# RX64M_PORT_Pilot register map
File version: 1.0
RX64M_PORT_Pilot peripheral registers generated from iodefine.h (pilot).
Registers are 8-bit, read-write, reset 0x0 unless marked. A register's access mark holds for its fields unless they carry their own. Offsets are from the block's base; lines under a group give offsets from that group; [hi:lo] are bit positions; {n}, {i} and the like mark numbered series; 'fields as' and 'values as' point back to an identical list; <NAME> marks a mode.

## Memory map
0x0008C000 PORT0 size 0xE1
0x0008C001 PORT1 size 0xC1
0x0008C002 PORT2 size 0xE1
0x0008C003 PORT3 size 0xC1
0x0008C004 PORT4 size 0xC1
0x0008C005 PORT5 size 0xE1
0x0008C006 PORT6 size 0xC1
0x0008C007 PORT7 size 0xC1
0x0008C008 PORT8 size 0xC1
0x0008C009 PORT9 size 0xE1
0x0008C00A PORTA size 0xE1
0x0008C00B PORTB size 0xE1
0x0008C00C PORTC size 0xE1
0x0008C00D PORTD size 0xE1
0x0008C00E PORTE size 0xE1
0x0008C00F PORTF size 0xC1
0x0008C010 PORTG size 0xE1
0x0008C012 PORTJ size 0xC1

## PORT0
Base 0x0008C000
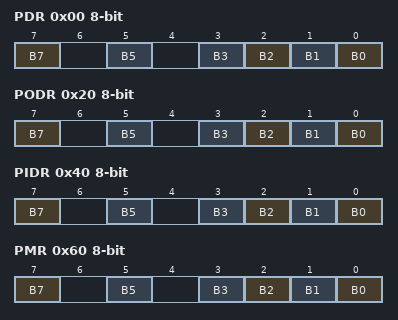
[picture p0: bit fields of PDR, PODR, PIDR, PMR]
0x00 PDR
  [7] B7, [5] B5, [n] B{n} (n=0..3)
0x20 PODR
  [7] B7, [5] B5, [n] B{n} (n=0..3)
0x40 PIDR ro reset not defined
  [7] B7, [5] B5, [n] B{n} (n=0..3)
0x60 PMR
  [7] B7, [5] B5, [n] B{n} (n=0..3)
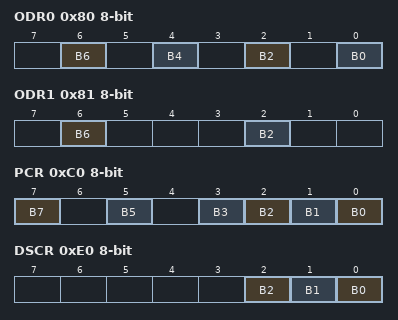
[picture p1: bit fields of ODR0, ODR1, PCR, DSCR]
0x80 ODR0
  [6] B6, [4] B4, [2] B2, [0] B0
0x81 ODR1
  [6] B6, [2] B2
0xC0 PCR
  [7] B7, [5] B5, [n] B{n} (n=0..3)
0xE0 DSCR
  [2] B2, [1] B1, [0] B0

## PORT1
Base 0x0008C001
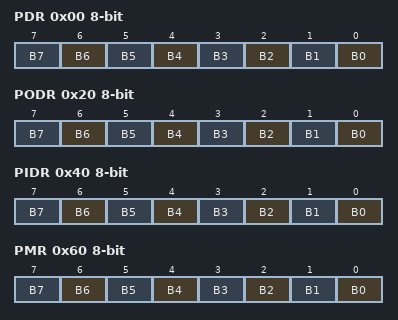
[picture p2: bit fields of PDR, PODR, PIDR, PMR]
0x00 PDR
  [n] B{n} (n=0..7)
0x20 PODR
  [n] B{n} (n=0..7)
0x40 PIDR ro reset not defined
  [n] B{n} (n=0..7)
0x60 PMR
  [n] B{n} (n=0..7)
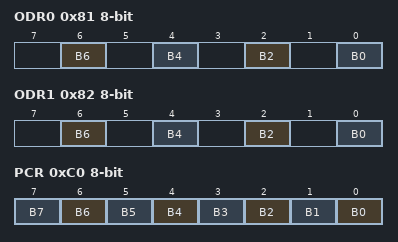
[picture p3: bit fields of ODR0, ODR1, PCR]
0x81 ODR0
  [6] B6, [4] B4, [2] B2, [0] B0
0x82 ODR1
  [6] B6, [4] B4, [2] B2, [0] B0
0xC0 PCR
  [n] B{n} (n=0..7)

## PORT2
Base 0x0008C002
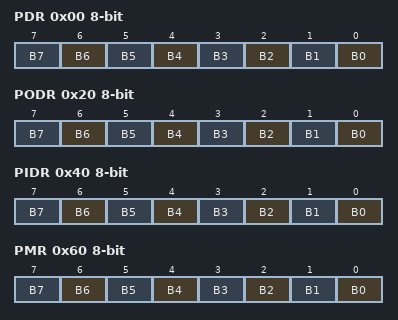
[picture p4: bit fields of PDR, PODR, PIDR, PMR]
0x00 PDR
  [n] B{n} (n=0..7)
0x20 PODR
  [n] B{n} (n=0..7)
0x40 PIDR ro reset not defined
  [n] B{n} (n=0..7)
0x60 PMR
  [n] B{n} (n=0..7)
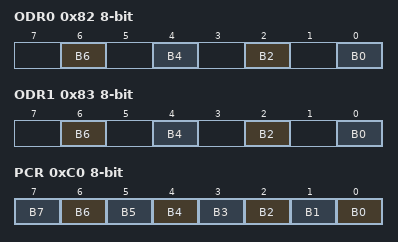
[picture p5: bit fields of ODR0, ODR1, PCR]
0x82 ODR0
  [6] B6, [4] B4, [2] B2, [0] B0
0x83 ODR1
  [6] B6, [4] B4, [2] B2, [0] B0
0xC0 PCR
  [n] B{n} (n=0..7)
0xE0 DSCR
  [7] B7

## PORT3
Base 0x0008C003
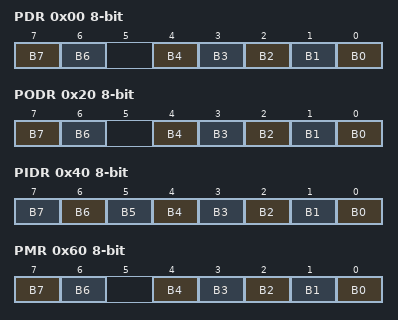
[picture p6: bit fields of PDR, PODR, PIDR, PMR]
0x00 PDR
  [7] B7, [6] B6, [n] B{n} (n=0..4)
0x20 PODR
  [7] B7, [6] B6, [n] B{n} (n=0..4)
0x40 PIDR ro reset not defined
  [n] B{n} (n=0..7)
0x60 PMR
  [7] B7, [6] B6, [n] B{n} (n=0..4)
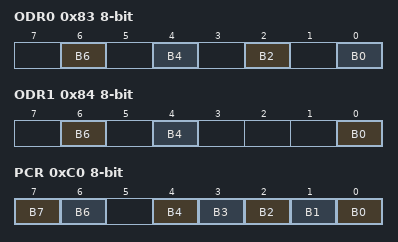
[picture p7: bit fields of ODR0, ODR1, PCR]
0x83 ODR0
  [6] B6, [4] B4, [2] B2, [0] B0
0x84 ODR1
  [6] B6, [4] B4, [0] B0
0xC0 PCR
  [7] B7, [6] B6, [n] B{n} (n=0..4)

## PORT4
Base 0x0008C004
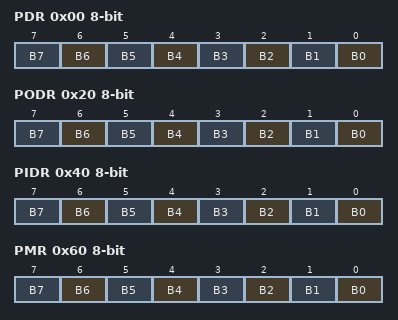
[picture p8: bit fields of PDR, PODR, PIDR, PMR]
0x00 PDR
  [n] B{n} (n=0..7)
0x20 PODR
  [n] B{n} (n=0..7)
0x40 PIDR ro reset not defined
  [n] B{n} (n=0..7)
0x60 PMR
  [n] B{n} (n=0..7)
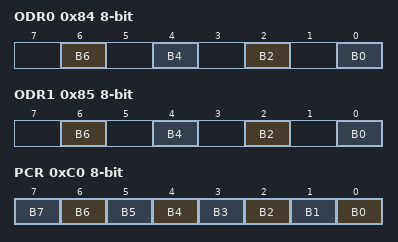
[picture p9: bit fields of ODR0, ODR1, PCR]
0x84 ODR0
  [6] B6, [4] B4, [2] B2, [0] B0
0x85 ODR1
  [6] B6, [4] B4, [2] B2, [0] B0
0xC0 PCR
  [n] B{n} (n=0..7)

## PORT5
Base 0x0008C005
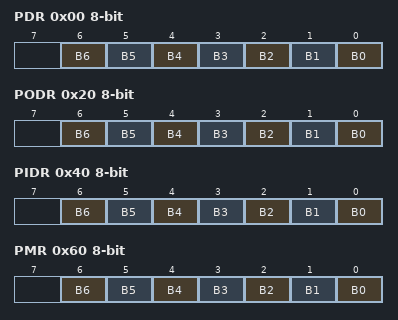
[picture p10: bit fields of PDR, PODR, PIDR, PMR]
0x00 PDR
  [n] B{n} (n=0..6)
0x20 PODR
  [n] B{n} (n=0..6)
0x40 PIDR ro reset not defined
  [n] B{n} (n=0..6)
0x60 PMR
  [n] B{n} (n=0..6)
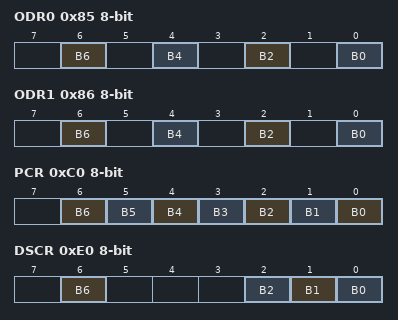
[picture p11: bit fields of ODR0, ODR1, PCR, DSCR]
0x85 ODR0
  [6] B6, [4] B4, [2] B2, [0] B0
0x86 ODR1
  [6] B6, [4] B4, [2] B2, [0] B0
0xC0 PCR
  [n] B{n} (n=0..6)
0xE0 DSCR
  [6] B6, [2] B2, [1] B1, [0] B0

## PORT6
Base 0x0008C006
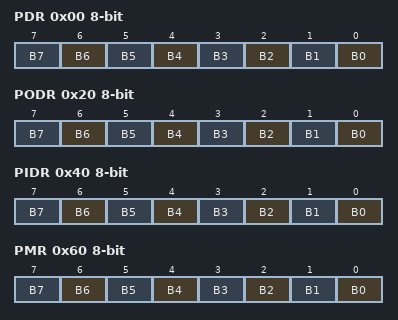
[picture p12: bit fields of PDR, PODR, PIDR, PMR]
0x00 PDR
  [n] B{n} (n=0..7)
0x20 PODR
  [n] B{n} (n=0..7)
0x40 PIDR ro reset not defined
  [n] B{n} (n=0..7)
0x60 PMR
  [n] B{n} (n=0..7)
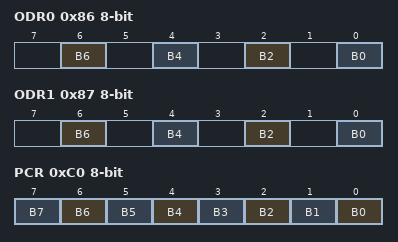
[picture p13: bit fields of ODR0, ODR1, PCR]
0x86 ODR0
  [6] B6, [4] B4, [2] B2, [0] B0
0x87 ODR1
  [6] B6, [4] B4, [2] B2, [0] B0
0xC0 PCR
  [n] B{n} (n=0..7)

## PORT7
Base 0x0008C007
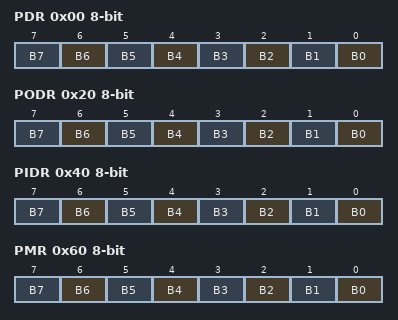
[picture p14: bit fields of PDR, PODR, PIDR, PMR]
0x00 PDR
  [n] B{n} (n=0..7)
0x20 PODR
  [n] B{n} (n=0..7)
0x40 PIDR ro reset not defined
  [n] B{n} (n=0..7)
0x60 PMR
  [n] B{n} (n=0..7)
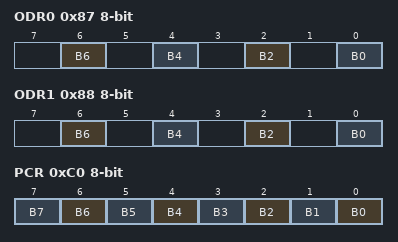
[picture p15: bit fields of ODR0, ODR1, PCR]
0x87 ODR0
  [6] B6, [4] B4, [2] B2, [0] B0
0x88 ODR1
  [6] B6, [4] B4, [2] B2, [0] B0
0xC0 PCR
  [n] B{n} (n=0..7)

## PORT8
Base 0x0008C008
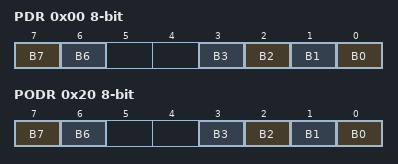
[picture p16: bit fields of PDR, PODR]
0x00 PDR
  [7] B7, [6] B6, [n] B{n} (n=0..3)
0x20 PODR
  [7] B7, [6] B6, [n] B{n} (n=0..3)
0x40 PIDR ro reset not defined
  [7] B7, [6] B6, [n] B{n} (n=0..3)
0x60 PMR
  [7] B7, [6] B6, [n] B{n} (n=0..3)
0x88 ODR0
  [6] B6, [4] B4, [2] B2, [0] B0
0x89 ODR1
  [6] B6, [4] B4
0xC0 PCR
  [7] B7, [6] B6, [n] B{n} (n=0..3)

## PORT9
Base 0x0008C009
0x00 PDR
  [n] B{n} (n=0..7)
0x20 PODR
  [n] B{n} (n=0..7)
0x40 PIDR ro reset not defined
  [n] B{n} (n=0..7)
0x60 PMR
  [n] B{n} (n=0..7)
0x89 ODR0
  [6] B6, [4] B4, [2] B2, [0] B0
0x8A ODR1
  [6] B6, [4] B4, [2] B2, [0] B0
0xC0 PCR
  [n] B{n} (n=0..7)
0xE0 DSCR
  [n] B{n} (n=0..7)

## PORTA
Base 0x0008C00A
0x00 PDR
  [n] B{n} (n=0..7)
0x20 PODR
  [n] B{n} (n=0..7)
0x40 PIDR ro reset not defined
  [n] B{n} (n=0..7)
0x60 PMR
  [n] B{n} (n=0..7)
0x8A ODR0
  [6] B6, [4] B4, [2] B2, [0] B0
0x8B ODR1
  [6] B6, [4] B4, [2] B2, [0] B0
0xC0 PCR
  [n] B{n} (n=0..7)
0xE0 DSCR
  [n] B{n} (n=0..7)

## PORTB
Base 0x0008C00B
0x00 PDR
  [n] B{n} (n=0..7)
0x20 PODR
  [n] B{n} (n=0..7)
0x40 PIDR ro reset not defined
  [n] B{n} (n=0..7)
0x60 PMR
  [n] B{n} (n=0..7)
0x8B ODR0
  [6] B6, [4] B4, [2] B2, [0] B0
0x8C ODR1
  [6] B6, [4] B4, [2] B2, [0] B0
0xC0 PCR
  [n] B{n} (n=0..7)
0xE0 DSCR
  [n] B{n} (n=0..7)

## PORTC
Base 0x0008C00C
0x00 PDR
  [n] B{n} (n=0..7)
0x20 PODR
  [n] B{n} (n=0..7)
0x40 PIDR ro reset not defined
  [n] B{n} (n=0..7)
0x60 PMR
  [n] B{n} (n=0..7)
0x8C ODR0
  [6] B6, [4] B4, [2] B2, [0] B0
0x8D ODR1
  [6] B6, [4] B4, [2] B2, [0] B0
0xC0 PCR
  [n] B{n} (n=0..7)
0xE0 DSCR
  [n] B{n} (n=0..7)

## PORTD
Base 0x0008C00D
0x00 PDR
  [n] B{n} (n=0..7)
0x20 PODR
  [n] B{n} (n=0..7)
0x40 PIDR ro reset not defined
  [n] B{n} (n=0..7)
0x60 PMR
  [n] B{n} (n=0..7)
0x8D ODR0
  [6] B6, [4] B4, [2] B2, [0] B0
0x8E ODR1
  [6] B6, [4] B4, [2] B2, [0] B0
0xC0 PCR
  [n] B{n} (n=0..7)
0xE0 DSCR
  [n] B{n} (n=0..7)

## PORTE
Base 0x0008C00E
0x00 PDR
  [n] B{n} (n=0..7)
0x20 PODR
  [n] B{n} (n=0..7)
0x40 PIDR ro reset not defined
  [n] B{n} (n=0..7)
0x60 PMR
  [n] B{n} (n=0..7)
0x8E ODR0
  [6] B6, [4] B4, [3] B3, [2] B2, [0] B0
0x8F ODR1
  [6] B6, [4] B4, [2] B2, [0] B0
0xC0 PCR
  [n] B{n} (n=0..7)
0xE0 DSCR
  [n] B{n} (n=0..7)

## PORTF
Base 0x0008C00F
0x00 PDR
  [n] B{n} (n=0..5)
0x20 PODR
  [n] B{n} (n=0..5)
0x40 PIDR ro reset not defined
  [n] B{n} (n=0..5)
0x60 PMR
  [n] B{n} (n=0..5)
0x8F ODR0
  [6] B6, [4] B4, [2] B2, [0] B0
0x90 ODR1
  [2] B2, [0] B0
0xC0 PCR
  [n] B{n} (n=0..5)

## PORTG
Base 0x0008C010
0x00 PDR
  [n] B{n} (n=0..7)
0x20 PODR
  [n] B{n} (n=0..7)
0x40 PIDR ro reset not defined
  [n] B{n} (n=0..7)
0x60 PMR
  [n] B{n} (n=0..7)
0x90 ODR0
  [6] B6, [4] B4, [2] B2, [0] B0
0x91 ODR1
  [6] B6, [4] B4, [2] B2, [0] B0
0xC0 PCR
  [n] B{n} (n=0..7)
0xE0 DSCR
  [1] B1, [0] B0

## PORTJ
Base 0x0008C012
0x00 PDR
  [5] B5, [3] B3
0x20 PODR
  [5] B5, [3] B3
0x40 PIDR ro reset not defined
  [5] B5, [3] B3
0x60 PMR
  [5] B5, [3] B3
0x92 ODR0
  [6] B6
0x93 ODR1
  [2] B2
0xC0 PCR
  [5] B5, [3] B3
